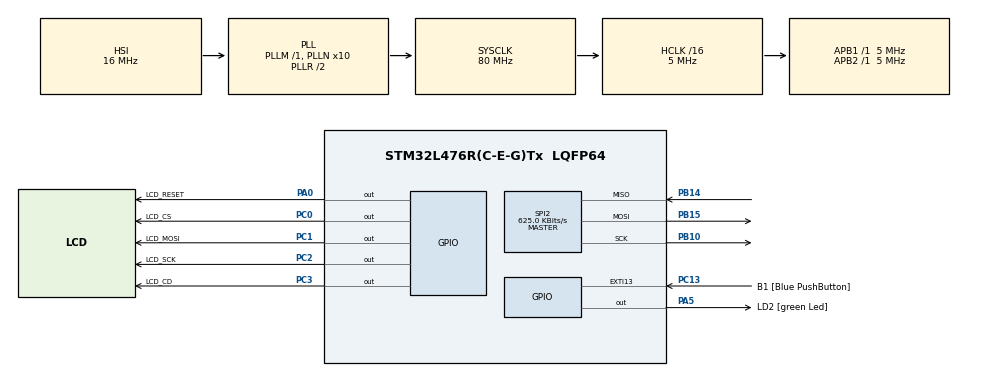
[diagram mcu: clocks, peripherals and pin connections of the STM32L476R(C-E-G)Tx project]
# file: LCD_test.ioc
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Mcu.Family=STM32L4
Mcu.Name=STM32L476R(C-E-G)Tx
Mcu.Package=LQFP64
NVIC.PriorityGroup=NVIC_PRIORITYGROUP_4
PA0.GPIO_Label=LCD_RESET
PA0.Signal=GPIO_Output
PA13.GPIO_Label=TMS
PA13.Signal=SYS_JTMS-SWDIO
PA14.GPIO_Label=TCK
PA14.Signal=SYS_JTCK-SWCLK
PA2.GPIO_Label=USART_TX
PA2.GPIO_Mode=GPIO_MODE_AF_PP
PA2.GPIO_PuPd=GPIO_NOPULL
PA2.GPIO_Speed=GPIO_SPEED_FREQ_VERY_HIGH
PA2.Signal=USART2_TX
PA3.GPIO_Label=USART_RX
PA3.GPIO_Mode=GPIO_MODE_AF_PP
PA3.GPIO_PuPd=GPIO_NOPULL
PA3.GPIO_Speed=GPIO_SPEED_FREQ_VERY_HIGH
PA3.Signal=USART2_RX
PA5.GPIO_Label=LD2 [green Led]
PA5.GPIO_ModeDefaultOutputPP=GPIO_MODE_OUTPUT_PP
PA5.GPIO_PuPd=GPIO_NOPULL
PA5.GPIO_Speed=GPIO_SPEED_FREQ_LOW
PA5.Signal=GPIO_Output
PB10.Mode=Full_Duplex_Master
PB10.Signal=SPI2_SCK
PB14.Mode=Full_Duplex_Master
PB14.Signal=SPI2_MISO
PB15.Mode=Full_Duplex_Master
PB15.Signal=SPI2_MOSI
PB3.GPIO_Label=SWO
PB3.Signal=SYS_JTDO-SWO
PC0.GPIO_Label=LCD_CS
PC0.Signal=GPIO_Output
PC1.GPIO_Label=LCD_MOSI
PC1.Signal=GPIO_Output
PC13.GPIO_Label=B1 [Blue PushButton]
PC13.GPIO_ModeDefaultEXTI=GPIO_MODE_IT_FALLING
PC13.GPIO_PuPd=GPIO_NOPULL
PC13.Signal=GPXTI13
PC14/OSC32_IN.Signal=RCC_OSC32_IN
PC15/OSC32_OUT.Signal=RCC_OSC32_OUT
PC2.GPIO_Label=LCD_SCK
PC2.Signal=GPIO_Output
PC3.GPIO_Label=LCD_CD
PC3.Signal=GPIO_Output
PH0/OSC_IN.Mode=HSE-External-Oscillator
PH0/OSC_IN.Signal=RCC_OSC_IN
PH1/OSC_OUT.Mode=HSE-External-Oscillator
PH1/OSC_OUT.Signal=RCC_OSC_OUT
ProjectManager.HeapSize=0x200
ProjectManager.StackSize=0x400
ProjectManager.TargetToolchain=TrueSTUDIO
RCC.ADCFreq_Value=64000000
RCC.AHBCLKDivider=RCC_SYSCLK_DIV16
RCC.AHBFreq_Value=5000000
RCC.APB1Freq_Value=5000000
RCC.APB1TimFreq_Value=5000000
RCC.APB2Freq_Value=5000000
RCC.APB2TimFreq_Value=5000000
RCC.ClockTypeHCLK=RCC_CLOCKTYPE_HCLK
RCC.ClockTypePCLK1=RCC_CLOCKTYPE_PCLK1
RCC.ClockTypePCLK2=RCC_CLOCKTYPE_PCLK2
RCC.ClockTypeSysClk=RCC_CLOCKTYPE_SYSCLK
RCC.CortexFreq_Value=5000000
RCC.EnableCSSLSE=false
RCC.EnbaleCSS=false
RCC.HCLKFreq_Value=5000000
RCC.HSI_VALUE=16000000
RCC.LSE_VALUE=32768
RCC.MSI_VALUE=4000000
RCC.PLLN=10
RCC.PLLSourceVirtual=RCC_PLLSOURCE_HSI
RCC.PREFETCH_ENABLE=1
RCC.SYSCLKFreq_VALUE=80000000
RCC.SYSCLKSource=RCC_SYSCLKSOURCE_PLLCLK
RCC.USBFreq_Value=64000000
RCC.VCOOutputFreq_Value=160000000
SPI2.BaudRatePrescaler=SPI_BAUDRATEPRESCALER_8
SPI2.CLKPhase=SPI_PHASE_2EDGE
SPI2.CRCLength=SPI_CRC_LENGTH_DATASIZE
SPI2.CRCPolynomial=7
SPI2.CalculateBaudRate=625.0 KBits/s
SPI2.DataSize=SPI_DATASIZE_8BIT
SPI2.Direction=SPI_DIRECTION_2LINES
SPI2.Mode=SPI_MODE_MASTER
SPI2.NSSPMode=SPI_NSS_PULSE_DISABLE
SPI2.VirtualType=VM_MASTER
TIM7.TIM_MasterSlaveMode=TIM_MASTERSLAVEMODE_DISABLE
VP_TIM7_VS_ClockSourceINT.Mode=Enable_Timer
board=NUCLEO-L476RG

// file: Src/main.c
/**
 ******************************************************************************
 * File Name          : main.c
 * Description        : Main program body
 ******************************************************************************
 *
 * COPYRIGHT(c) 2019 STMicroelectronics
 *
 * Redistribution and use in source and binary forms, with or without modification,
 * are permitted provided that the following conditions are met:
 *   1. Redistributions of source code must retain the above copyright notice,
 *      this list of conditions and the following disclaimer.
 *   2. Redistributions in binary form must reproduce the above copyright notice,
 *      this list of conditions and the following disclaimer in the documentation
 *      and/or other materials provided with the distribution.
 *   3. Neither the name of STMicroelectronics nor the names of its contributors
 *      may be used to endorse or promote products derived from this software
 *      without specific prior written permission.
 *
 * THIS SOFTWARE IS PROVIDED BY THE COPYRIGHT HOLDERS AND CONTRIBUTORS "AS IS"
 * AND ANY EXPRESS OR IMPLIED WARRANTIES, INCLUDING, BUT NOT LIMITED TO, THE
 * IMPLIED WARRANTIES OF MERCHANTABILITY AND FITNESS FOR A PARTICULAR PURPOSE ARE
 * DISCLAIMED. IN NO EVENT SHALL THE COPYRIGHT HOLDER OR CONTRIBUTORS BE LIABLE
 * FOR ANY DIRECT, INDIRECT, INCIDENTAL, SPECIAL, EXEMPLARY, OR CONSEQUENTIAL
 * DAMAGES (INCLUDING, BUT NOT LIMITED TO, PROCUREMENT OF SUBSTITUTE GOODS OR
 * SERVICES; LOSS OF USE, DATA, OR PROFITS; OR BUSINESS INTERRUPTION) HOWEVER
 * CAUSED AND ON ANY THEORY OF LIABILITY, WHETHER IN CONTRACT, STRICT LIABILITY,
 * OR TORT (INCLUDING NEGLIGENCE OR OTHERWISE) ARISING IN ANY WAY OUT OF THE USE
 * OF THIS SOFTWARE, EVEN IF ADVISED OF THE POSSIBILITY OF SUCH DAMAGE.
 *
 ******************************************************************************
 */
#include "main.h"
#include "stm32l4xx_hal.h"

/* USER CODE BEGIN Includes */
#include "DogLCD.h"
/* USER CODE END Includes */

SPI_HandleTypeDef hspi2;

TIM_HandleTypeDef htim7;

/* USER CODE BEGIN PV */
/* Private variables ---------------------------------------------------------*/
uint8_t message[] = "Hejhej";
uint8_t buttonDownRight;
uint8_t buttonTopRight;
uint8_t buttonTopLeft;

/* USER CODE END PV */

void SystemClock_Config(void);
void Error_Handler(void);
static void MX_GPIO_Init(void);
static void MX_TIM7_Init(void);
static void MX_SPI2_Init(void);

/* USER CODE BEGIN PFP */
/* Private function prototypes -----------------------------------------------*/

/* USER CODE END PFP */

int main(void)
{

	/* MCU Configuration----------------------------------------------------------*/

	/* Reset of all peripherals, Initializes the Flash interface and the Systick. */
	HAL_Init();

	/* Configure the system clock */
	SystemClock_Config();

	/* Initialize all configured peripherals */
	MX_GPIO_Init();
	MX_TIM7_Init();
	MX_SPI2_Init();

	/* USER CODE BEGIN 2 */
	initLCD();
	/* USER CODE END 2 */

	/* Infinite loop */
	/* USER CODE BEGIN WHILE */
	HAL_Delay(2000);
	printStartScreen();

	while (1)
	{
		/* USER CODE END WHILE */

	}

}

/** System Clock Configuration
 */
void SystemClock_Config(void)
{

	RCC_OscInitTypeDef RCC_OscInitStruct;
	RCC_ClkInitTypeDef RCC_ClkInitStruct;

	/**Initializes the CPU, AHB and APB busses clocks
	 */
	RCC_OscInitStruct.OscillatorType = RCC_OSCILLATORTYPE_HSI;
	RCC_OscInitStruct.HSIState = RCC_HSI_ON;
	RCC_OscInitStruct.HSICalibrationValue = 16;
	RCC_OscInitStruct.PLL.PLLState = RCC_PLL_ON;
	RCC_OscInitStruct.PLL.PLLSource = RCC_PLLSOURCE_HSI;
	RCC_OscInitStruct.PLL.PLLM = 1;
	RCC_OscInitStruct.PLL.PLLN = 10;
	RCC_OscInitStruct.PLL.PLLP = RCC_PLLP_DIV7;
	RCC_OscInitStruct.PLL.PLLQ = RCC_PLLQ_DIV2;
	RCC_OscInitStruct.PLL.PLLR = RCC_PLLR_DIV2;
	if (HAL_RCC_OscConfig(&RCC_OscInitStruct) != HAL_OK)
	{
		Error_Handler();
	}

	/**Initializes the CPU, AHB and APB busses clocks
	 */
	RCC_ClkInitStruct.ClockType = RCC_CLOCKTYPE_HCLK|RCC_CLOCKTYPE_SYSCLK
			|RCC_CLOCKTYPE_PCLK1|RCC_CLOCKTYPE_PCLK2;
	RCC_ClkInitStruct.SYSCLKSource = RCC_SYSCLKSOURCE_PLLCLK;
	RCC_ClkInitStruct.AHBCLKDivider = RCC_SYSCLK_DIV16;
	RCC_ClkInitStruct.APB1CLKDivider = RCC_HCLK_DIV1;
	RCC_ClkInitStruct.APB2CLKDivider = RCC_HCLK_DIV1;

	if (HAL_RCC_ClockConfig(&RCC_ClkInitStruct, FLASH_LATENCY_0) != HAL_OK)
	{
		Error_Handler();
	}

	/**Configure the main internal regulator output voltage
	 */
	if (HAL_PWREx_ControlVoltageScaling(PWR_REGULATOR_VOLTAGE_SCALE1) != HAL_OK)
	{
		Error_Handler();
	}

	/**Configure the Systick interrupt time
	 */
	HAL_SYSTICK_Config(HAL_RCC_GetHCLKFreq()/1000);

	/**Configure the Systick
	 */
	HAL_SYSTICK_CLKSourceConfig(SYSTICK_CLKSOURCE_HCLK);

	/* SysTick_IRQn interrupt configuration */
	HAL_NVIC_SetPriority(SysTick_IRQn, 0, 0);
}

/* SPI2 init function */
static void MX_SPI2_Init(void)
{

	hspi2.Instance = SPI2;
	hspi2.Init.Mode = SPI_MODE_MASTER;
	hspi2.Init.Direction = SPI_DIRECTION_2LINES;
	hspi2.Init.DataSize = SPI_DATASIZE_8BIT;
	hspi2.Init.CLKPolarity = SPI_POLARITY_LOW;
	hspi2.Init.CLKPhase = SPI_PHASE_2EDGE;
	hspi2.Init.NSS = SPI_NSS_SOFT;
	hspi2.Init.BaudRatePrescaler = SPI_BAUDRATEPRESCALER_8;
	hspi2.Init.FirstBit = SPI_FIRSTBIT_MSB;
	hspi2.Init.TIMode = SPI_TIMODE_DISABLE;
	hspi2.Init.CRCCalculation = SPI_CRCCALCULATION_DISABLE;
	hspi2.Init.CRCPolynomial = 7;
	hspi2.Init.CRCLength = SPI_CRC_LENGTH_DATASIZE;
	hspi2.Init.NSSPMode = SPI_NSS_PULSE_DISABLE;
	if (HAL_SPI_Init(&hspi2) != HAL_OK)
	{
		Error_Handler();
	}

}

/* TIM7 init function */
static void MX_TIM7_Init(void)
{

	TIM_MasterConfigTypeDef sMasterConfig;

	htim7.Instance = TIM7;
	htim7.Init.Prescaler = 0;
	htim7.Init.CounterMode = TIM_COUNTERMODE_UP;
	htim7.Init.Period = 0;
	if (HAL_TIM_Base_Init(&htim7) != HAL_OK)
	{
		Error_Handler();
	}

	sMasterConfig.MasterOutputTrigger = TIM_TRGO_RESET;
	sMasterConfig.MasterSlaveMode = TIM_MASTERSLAVEMODE_DISABLE;
	if (HAL_TIMEx_MasterConfigSynchronization(&htim7, &sMasterConfig) != HAL_OK)
	{
		Error_Handler();
	}

}

/** Configure pins as
 * Analog
 * Input
 * Output
 * EVENT_OUT
 * EXTI
     PA2   ------> USART2_TX
     PA3   ------> USART2_RX
 */
static void MX_GPIO_Init(void)
{

	GPIO_InitTypeDef GPIO_InitStruct;

	/* GPIO Ports Clock Enable */
	__HAL_RCC_GPIOC_CLK_ENABLE();
	__HAL_RCC_GPIOH_CLK_ENABLE();
	__HAL_RCC_GPIOA_CLK_ENABLE();
	__HAL_RCC_GPIOB_CLK_ENABLE();

	/*Configure GPIO pin Output Level */
	HAL_GPIO_WritePin(GPIOC, LCD_CS_Pin|LCD_MOSI_Pin|LCD_SCK_Pin|LCD_CD_Pin, GPIO_PIN_RESET);

	/*Configure GPIO pin Output Level */
	HAL_GPIO_WritePin(GPIOA, LCD_RESET_Pin|LD2_Pin, GPIO_PIN_RESET);

	/*Configure GPIO pin : B1_Pin */
	GPIO_InitStruct.Pin = B1_Pin;
	GPIO_InitStruct.Mode = GPIO_MODE_IT_FALLING;
	GPIO_InitStruct.Pull = GPIO_NOPULL;
	HAL_GPIO_Init(B1_GPIO_Port, &GPIO_InitStruct);

	/*Configure GPIO pins : LCD_CS_Pin LCD_MOSI_Pin LCD_SCK_Pin LCD_CD_Pin */
	GPIO_InitStruct.Pin = LCD_CS_Pin|LCD_MOSI_Pin|LCD_SCK_Pin|LCD_CD_Pin;
	GPIO_InitStruct.Mode = GPIO_MODE_OUTPUT_PP;
	GPIO_InitStruct.Pull = GPIO_NOPULL;
	GPIO_InitStruct.Speed = GPIO_SPEED_FREQ_LOW;
	HAL_GPIO_Init(GPIOC, &GPIO_InitStruct);

	/*Configure GPIO pins : LCD_RESET_Pin LD2_Pin */
	GPIO_InitStruct.Pin = LCD_RESET_Pin|LD2_Pin;
	GPIO_InitStruct.Mode = GPIO_MODE_OUTPUT_PP;
	GPIO_InitStruct.Pull = GPIO_NOPULL;
	GPIO_InitStruct.Speed = GPIO_SPEED_FREQ_LOW;
	HAL_GPIO_Init(GPIOA, &GPIO_InitStruct);

	/*Configure GPIO pins : USART_TX_Pin USART_RX_Pin */
	GPIO_InitStruct.Pin = USART_TX_Pin|USART_RX_Pin;
	GPIO_InitStruct.Mode = GPIO_MODE_AF_PP;
	GPIO_InitStruct.Pull = GPIO_NOPULL;
	GPIO_InitStruct.Speed = GPIO_SPEED_FREQ_VERY_HIGH;
	GPIO_InitStruct.Alternate = GPIO_AF7_USART2;
	HAL_GPIO_Init(GPIOA, &GPIO_InitStruct);

}

void Error_Handler(void)
{
	while(1)
	{
	}
}

/************************ (C) COPYRIGHT STMicroelectronics *****END OF FILE****/
